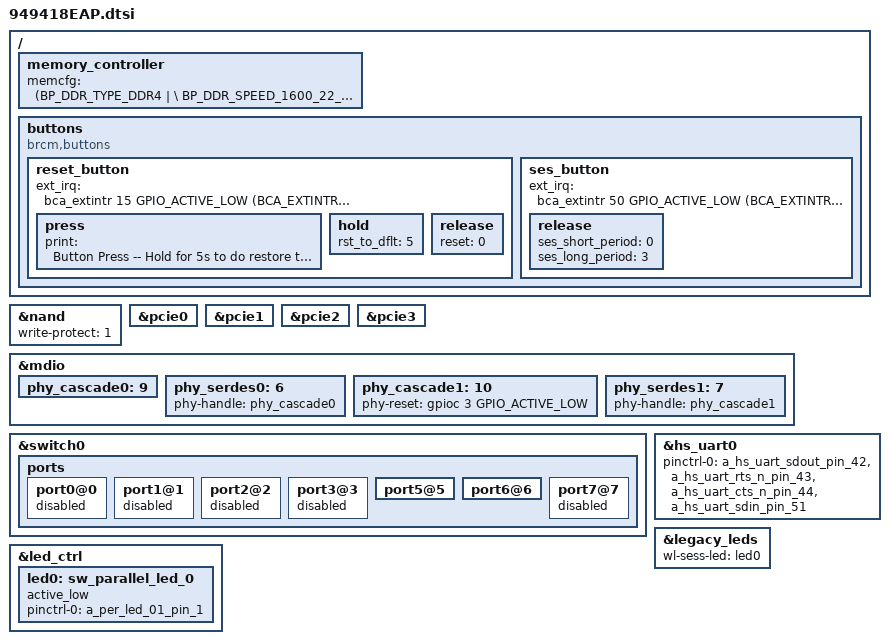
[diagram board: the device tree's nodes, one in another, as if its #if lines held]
#include "4912.dtsi"

/ {
	memory_controller {
		memcfg = <(BP_DDR_TYPE_DDR4           | \
			BP_DDR_SPEED_1600_22_22_22    | \
			BP_DDR_TOTAL_SIZE_2048MB      | \
			BP_DDR_DEVICE_WIDTH_16        | \
			BP_DDR_TOTAL_WIDTH_32BIT      | \
			BP_DDR_4912_DEFAULT)>;
    };
	buttons {
		compatible = "brcm,buttons";
		reset_button {
			ext_irq = <&bca_extintr 15 GPIO_ACTIVE_LOW (BCA_EXTINTR_TYPE_LOW_LEVEL | BCA_EXTINTR_TYPE_SENSE_EDGE)>;
			press {
				print = "Button Press -- Hold for 5s to do restore to default";
			};
			hold {
				rst_to_dflt = <5>;
			};
			release {
				reset = <0>;
			};	
		};
		ses_button {
			ext_irq = <&bca_extintr 50 GPIO_ACTIVE_LOW (BCA_EXTINTR_TYPE_LOW_LEVEL | BCA_EXTINTR_TYPE_SENSE_EDGE)>;
			release {
				ses_short_period = <0>;
				ses_long_period = <3>;
			};
		};
	};    
};

&nand {
	write-protect = <1>;
};

#if defined(CONFIG_BCM_PCIE_HCD) || defined(CONFIG_BCM_PCIE_HCD_MODULE)
&pcie0 {
	status = "okay";
};
&pcie1 {
	status = "okay";
};
&pcie2 {
	status = "okay";
};
&pcie3 {
	status = "okay";
};
#endif //#if defined(CONFIG_BCM_PCIE_HCD) || defined(CONFIG_BCM_PCIE_HCD_MODULE)

&mdio {
	phy_cascade0:9 {
		status = "okay";
	};

	phy_serdes0:6 {
		phy-handle = <&phy_cascade0>;
		status = "okay";
	};
	phy_cascade1:10 {
		phy-reset = <&gpioc 3 GPIO_ACTIVE_LOW>;
		status = "okay";
	};

	phy_serdes1:7 {
		phy-handle = <&phy_cascade1>;
		status = "okay";
	};
};

&switch0 {
	ports {
		port0@0 {
			status = "disabled";
		};

		port1@1 {
			status = "disabled";
		};

		port2@2 {
			status = "disabled";
		};

		port3@3 {
			status = "disabled";
		};

		port5@5 {
			status = "okay";
		};

		port6@6 {
			status = "okay";
		};

		port7@7 {
			status = "disabled";
		};
	};
};
&hs_uart0 {
	pinctrl-names = "default";
	pinctrl-0 = <&a_hs_uart_sdout_pin_42 &a_hs_uart_rts_n_pin_43 &a_hs_uart_cts_n_pin_44 &a_hs_uart_sdin_pin_51>;
	status = "okay";
};

&legacy_leds {
    wl-sess-led = <&led0>;
};

&led_ctrl {
	led0: sw_parallel_led_0 {
		active_low;
		pinctrl-0=<&a_per_led_01_pin_1>;
		status = "okay";
	};
};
